# STM32G484 register map
File version: 2.1
CPU: CM4 r0p1, little endian, MPU, FPU, 4 interrupt priority bits
Registers are 32-bit, read-write, reset 0x0 unless marked. A register's access mark holds for its fields unless they carry their own. Offsets are from the block's base; [hi:lo] are bit positions; {n}, {i} and the like mark numbered series; 'fields as' and 'values as' point back to an identical list.

## OPAMP — Operational amplifiers
Base 0x40010300
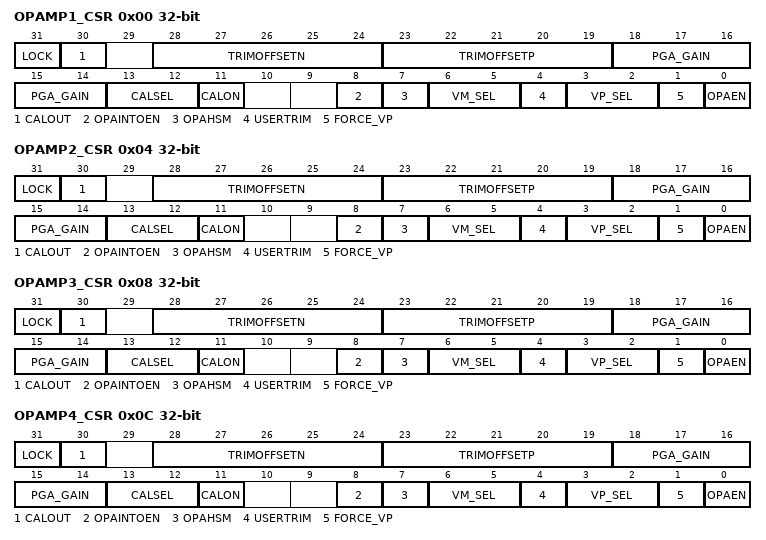
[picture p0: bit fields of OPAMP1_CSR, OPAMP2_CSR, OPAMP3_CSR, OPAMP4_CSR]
0x00 OPAMP1_CSR — OPAMP1 control/status register
  [31] LOCK
    0=ReadWrite (CSR is read-write); 1=ReadOnly (CSR is read-only, can only be cleared by system reset)
  [30] CALOUT
  [28:24] TRIMOFFSETN
  [23:19] TRIMOFFSETP
  [18:14] PGA_GAIN
    0=Gain2; 1=Gain4; 2=Gain8; 3=Gain16; 4=Gain32; 5=Gain64; 8=Gain2_InputVINM0 (Gain 2, input/bias connected to VINM0 or inverting gain); 9=Gain4_InputVINM0 (Gain 4, input/bias connected to VINM0 or inverting gain); 10=Gain8_InputVINM0 (Gain 8, input/bias connected to VINM0 or inverting gain); 11=Gain16_InputVINM0 (Gain 16, input/bias connected to VINM0 or inverting gain); 12=Gain32_InputVINM0 (Gain 32, input/bias connected to VINM0 or inverting gain); 13=Gain64_InputVINM0 (Gain 64, input/bias connected to VINM0 or inverting gain); 16=Gain2_FilteringVINM0 (Gain 2, with filtering on VINM0); 17=Gain4_FilteringVINM0 (Gain 4, with filtering on VINM0); 18=Gain8_FilteringVINM0 (Gain 8, with filtering on VINM0); 19=Gain16_FilteringVINM0 (Gain 16, with filtering on VINM0); 20=Gain32_FilteringVINM0 (Gain 32, with filtering on VINM0); 21=Gain64_FilteringVINM0 (Gain 64, with filtering on VINM0); 24=Gain2_InputVINM0FilteringVINM1 (Gain 2, input/bias connected to VINM0 with filtering on VINM1 or inverting gain); 25=Gain4_InputVINM0FilteringVINM1 (Gain 4, input/bias connected to VINM0 with filtering on VINM1 or inverting gain); 26=Gain8_InputVINM0FilteringVINM1 (Gain 8, input/bias connected to VINM0 with filtering on VINM1 or inverting gain); 27=Gain16_InputVINM0FilteringVINM1 (Gain 16, input/bias connected to VINM0 with filtering on VINM1 or inverting gain); 28=Gain32_InputVINM0FilteringVINM1 (Gain 32, input/bias connected to VINM0 with filtering on VINM1 or inverting gain); 29=Gain64_InputVINM0FilteringVINM1 (Gain 64, input/bias connected to VINM0 with filtering on VINM1 or inverting gain)
  [13:12] CALSEL
    0=Percent3_3 (0.033*VDDA applied to OPAMP inputs during calibration); 1=Percent10 (0.1*VDDA applied to OPAMP inputs during calibration); 2=Percent50 (0.5*VDDA applied to OPAMP inputs during calibration); 3=Percent90 (0.9*VDDA applied to OPAMP inputs during calibration)
  [11] CALON
    0=Disabled (Calibration mode disabled); 1=Enabled (Calibration mode enabled)
  [8] OPAINTOEN
    0=OutputPin (Output is connected to the output Pin); 1=ADCChannel (Output is connected internally to ADC channel)
  [7] OPAHSM
    0=Normal (OpAmp in normal mode); 1=HighSpeed (OpAmp in high speed mode)
  [6:5] VM_SEL
    0=VINM0 (VINM0 connected to VINM input); 1=VINM1 (VINM1 connected to VINM input); 2=PGA (Feedback resistor connected to VINM (PGA mode)); 3=Output (OpAmp output connected to VINM (Follower mode))
  [4] USERTRIM
    0=Factory trim used; 1=User trim used
  [3:2] VP_SEL
    0=VINP0 (VINP0 connected to VINP input); 1=VINP1 (VINP1 connected to VINP input); 2=VINP2 (VINP2 connected to VINP input); 3=DAC3_CH1 (DAC3_CH1 connected to VINP input)
  [1] FORCE_VP
    0=Normal (Non-inverting input connected configured inputs); 1=CalibrationVerification (Non-inverting input connected to calibration reference voltage)
  [0] OPAEN — Operational amplifier Enable
    0=Disabled (OpAmp disabled); 1=Enabled (OpAmp enabled)
0x04 OPAMP2_CSR — OPAMP2 control/status register
  [31] LOCK
    values as OPAMP1_CSR.LOCK
  [30] CALOUT
  [28:24] TRIMOFFSETN
  [23:19] TRIMOFFSETP
  [18:14] PGA_GAIN
    values as OPAMP1_CSR.PGA_GAIN
  [13:12] CALSEL
    values as OPAMP1_CSR.CALSEL
  [11] CALON
    values as OPAMP1_CSR.CALON
  [8] OPAINTOEN
    values as OPAMP1_CSR.OPAINTOEN
  [7] OPAHSM
    values as OPAMP1_CSR.OPAHSM
  [6:5] VM_SEL
    values as OPAMP1_CSR.VM_SEL
  [4] USERTRIM
    0=Factory trim used; 1=User trim used
  [3:2] VP_SEL
    {v}=VINP{v} (VINP{v} connected to VINP input) (v=0..3)
  [1] FORCE_VP
    values as OPAMP1_CSR.FORCE_VP
  [0] OPAEN — Operational amplifier Enable
    0=Disabled (OpAmp disabled); 1=Enabled (OpAmp enabled)
0x08 OPAMP3_CSR — OPAMP3 control/status register
  [31] LOCK
    values as OPAMP1_CSR.LOCK
  [30] CALOUT
  [28:24] TRIMOFFSETN
  [23:19] TRIMOFFSETP
  [18:14] PGA_GAIN
    values as OPAMP1_CSR.PGA_GAIN
  [13:12] CALSEL
    values as OPAMP1_CSR.CALSEL
  [11] CALON
    values as OPAMP1_CSR.CALON
  [8] OPAINTOEN
    values as OPAMP1_CSR.OPAINTOEN
  [7] OPAHSM
    values as OPAMP1_CSR.OPAHSM
  [6:5] VM_SEL
    values as OPAMP1_CSR.VM_SEL
  [4] USERTRIM
    0=Factory trim used; 1=User trim used
  [3:2] VP_SEL
    0=VINP0 (VINP0 connected to VINP input); 1=VINP1 (VINP1 connected to VINP input); 2=VINP2 (VINP2 connected to VINP input); 3=DAC3_CH2 (DAC3_CH2 connected to VINP input)
  [1] FORCE_VP
    values as OPAMP1_CSR.FORCE_VP
  [0] OPAEN — Operational amplifier Enable
    0=Disabled (OpAmp disabled); 1=Enabled (OpAmp enabled)
0x0C OPAMP4_CSR — OPAMP4 control/status register
  [31] LOCK
    values as OPAMP1_CSR.LOCK
  [30] CALOUT
  [28:24] TRIMOFFSETN
  [23:19] TRIMOFFSETP
  [18:14] PGA_GAIN
    values as OPAMP1_CSR.PGA_GAIN
  [13:12] CALSEL
    values as OPAMP1_CSR.CALSEL
  [11] CALON
    values as OPAMP1_CSR.CALON
  [8] OPAINTOEN
    values as OPAMP1_CSR.OPAINTOEN
  [7] OPAHSM
    values as OPAMP1_CSR.OPAHSM
  [6:5] VM_SEL
    values as OPAMP1_CSR.VM_SEL
  [4] USERTRIM
    0=Factory trim used; 1=User trim used
  [3:2] VP_SEL
    0=VINP0 (VINP0 connected to VINP input); 1=VINP1 (VINP1 connected to VINP input); 2=VINP2 (VINP2 connected to VINP input); 3=DAC4_CH1 (DAC4_CH1 connected to VINP input)
  [1] FORCE_VP
    values as OPAMP1_CSR.FORCE_VP
  [0] OPAEN — Operational amplifier Enable
    0=Disabled (OpAmp disabled); 1=Enabled (OpAmp enabled)
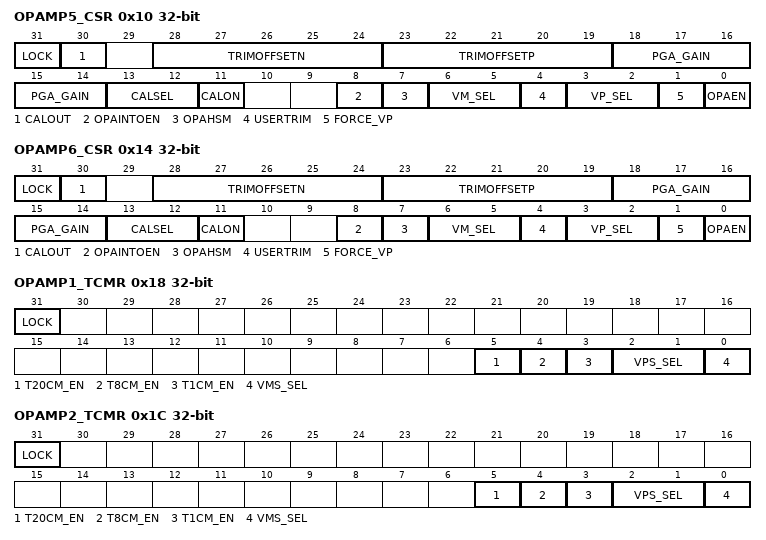
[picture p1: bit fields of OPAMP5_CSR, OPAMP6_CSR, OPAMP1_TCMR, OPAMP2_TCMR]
0x10 OPAMP5_CSR — OPAMP5 control/status register
  [31] LOCK
    values as OPAMP1_CSR.LOCK
  [30] CALOUT
  [28:24] TRIMOFFSETN
  [23:19] TRIMOFFSETP
  [18:14] PGA_GAIN
    values as OPAMP1_CSR.PGA_GAIN
  [13:12] CALSEL
    values as OPAMP1_CSR.CALSEL
  [11] CALON
    values as OPAMP1_CSR.CALON
  [8] OPAINTOEN
    values as OPAMP1_CSR.OPAINTOEN
  [7] OPAHSM
    values as OPAMP1_CSR.OPAHSM
  [6:5] VM_SEL
    values as OPAMP1_CSR.VM_SEL
  [4] USERTRIM
    0=Factory trim used; 1=User trim used
  [3:2] VP_SEL
    0=VINP0 (VINP0 connected to VINP input); 1=VINP1 (VINP1 connected to VINP input); 2=VINP2 (VINP2 connected to VINP input); 3=DAC4_CH2 (DAC4_CH2 connected to VINP input)
  [1] FORCE_VP
    values as OPAMP1_CSR.FORCE_VP
  [0] OPAEN — Operational amplifier Enable
    0=Disabled (OpAmp disabled); 1=Enabled (OpAmp enabled)
0x14 OPAMP6_CSR — OPAMP6 control/status register
  fields as OPAMP1_CSR
0x18 OPAMP1_TCMR — OPAMP1 control/status register
  [31] LOCK
    0=ReadWrite (TCMR is read-write); 1=ReadOnly (TCMR is read-only, can only be cleared by system reset)
  [5] T20CM_EN
    0=Disabled (Automatic input switch triggered by TIM20 disabled); 1=Enabled (Automatic input switch triggered by TIM20 enabled)
  [4] T8CM_EN
    0=Disabled (Automatic input switch triggered by TIM8 disabled); 1=Enabled (Automatic input switch triggered by TIM8 enabled)
  [3] T1CM_EN
    0=Disabled (Automatic input switch triggered by TIM1 disabled); 1=Enabled (Automatic input switch triggered by TIM1 enabled)
  [2:1] VPS_SEL
    values as OPAMP1_CSR.VP_SEL
  [0] VMS_SEL
0x1C OPAMP2_TCMR — OPAMP2 control/status register
  [31] LOCK
    values as OPAMP1_TCMR.LOCK
  [5] T20CM_EN
    values as OPAMP1_TCMR.T20CM_EN
  [4] T8CM_EN
    values as OPAMP1_TCMR.T8CM_EN
  [3] T1CM_EN
    values as OPAMP1_TCMR.T1CM_EN
  [2:1] VPS_SEL
    {v}=VINP{v} (VINP{v} connected to VINP input) (v=0..3)
  [0] VMS_SEL
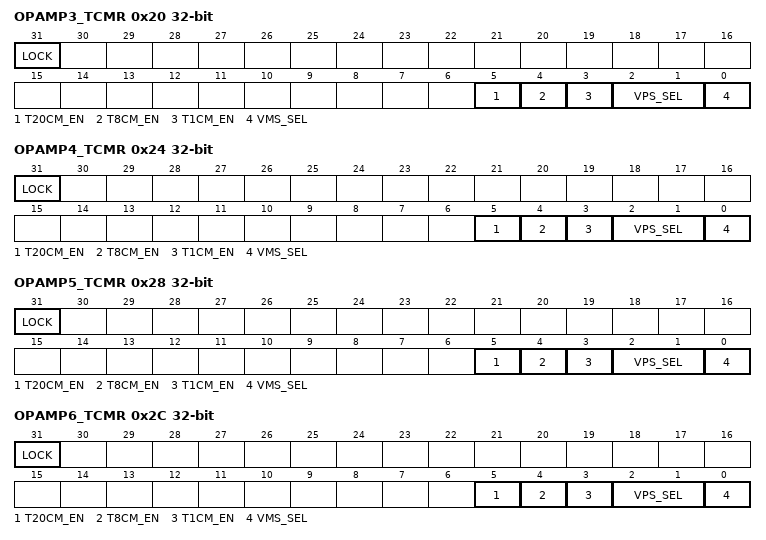
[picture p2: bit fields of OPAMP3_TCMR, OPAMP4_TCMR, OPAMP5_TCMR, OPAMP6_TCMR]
0x20 OPAMP3_TCMR — OPAMP3 control/status register
  [31] LOCK
    values as OPAMP1_TCMR.LOCK
  [5] T20CM_EN
    values as OPAMP1_TCMR.T20CM_EN
  [4] T8CM_EN
    values as OPAMP1_TCMR.T8CM_EN
  [3] T1CM_EN
    values as OPAMP1_TCMR.T1CM_EN
  [2:1] VPS_SEL
    values as OPAMP3_CSR.VP_SEL
  [0] VMS_SEL
0x24 OPAMP4_TCMR — OPAMP4 control/status register
  [31] LOCK
    values as OPAMP1_TCMR.LOCK
  [5] T20CM_EN
    values as OPAMP1_TCMR.T20CM_EN
  [4] T8CM_EN
    values as OPAMP1_TCMR.T8CM_EN
  [3] T1CM_EN
    values as OPAMP1_TCMR.T1CM_EN
  [2:1] VPS_SEL
    values as OPAMP4_CSR.VP_SEL
  [0] VMS_SEL
0x28 OPAMP5_TCMR — OPAMP5 control/status register
  [31] LOCK
    values as OPAMP1_TCMR.LOCK
  [5] T20CM_EN
    values as OPAMP1_TCMR.T20CM_EN
  [4] T8CM_EN
    values as OPAMP1_TCMR.T8CM_EN
  [3] T1CM_EN
    values as OPAMP1_TCMR.T1CM_EN
  [2:1] VPS_SEL
    values as OPAMP5_CSR.VP_SEL
  [0] VMS_SEL
0x2C OPAMP6_TCMR — OPAMP6 control/status register
  fields as OPAMP1_TCMR
